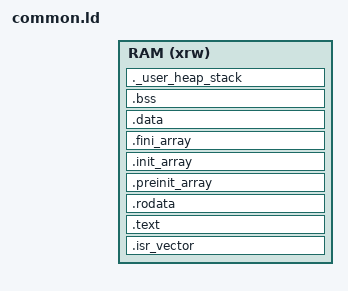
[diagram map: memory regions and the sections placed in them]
/* Common config for gcc's linker, as called from PlatformIO. Needs "ram.ld". */

/* Entry Point */
ENTRY(Reset_Handler)

_estack = ORIGIN(RAM) + LENGTH(RAM); /* end of "RAM" Ram type memory */

INCLUDE ram.ld
MEMORY
{
  RAM (xrw) : ORIGIN = RAM_BASE, LENGTH = RAM_SIZE
}

SECTIONS
{
  .isr_vector :
  {
    . = ALIGN(4);
    KEEP(*(.isr_vector))
    . = ALIGN(4);
  } >RAM

  .text :
  {
    . = ALIGN(4);
    *(.text)           /* .text sections (code) */
    *(.text*)          /* .text* sections (code) */
    *(.glue_7)         /* glue arm to thumb code */
    *(.glue_7t)        /* glue thumb to arm code */
    *(.eh_frame)

    KEEP (*(.init))
    KEEP (*(.fini))

    . = ALIGN(4);
    _etext = .;
  } >RAM

  .rodata :
  {
    . = ALIGN(4);
    *(.rodata)         /* .rodata sections (constants, strings, etc.) */
    *(.rodata*)        /* .rodata* sections (constants, strings, etc.) */
    . = ALIGN(4);
  } >RAM

  .preinit_array     :
  {
    . = ALIGN(4);
    PROVIDE_HIDDEN (__preinit_array_start = .);
    KEEP (*(.preinit_array*))
    PROVIDE_HIDDEN (__preinit_array_end = .);
    . = ALIGN(4);
  } >RAM

  .init_array :
  {
    . = ALIGN(4);
    PROVIDE_HIDDEN (__init_array_start = .);
    KEEP (*(SORT(.init_array.*)))
    KEEP (*(.init_array*))
    PROVIDE_HIDDEN (__init_array_end = .);
    . = ALIGN(4);
  } >RAM

  .fini_array :
  {
    . = ALIGN(4);
    PROVIDE_HIDDEN (__fini_array_start = .);
    KEEP (*(SORT(.fini_array.*)))
    KEEP (*(.fini_array*))
    PROVIDE_HIDDEN (__fini_array_end = .);
    . = ALIGN(4);
  } >RAM

  _sidata = LOADADDR(.data);

  .data :
  {
    . = ALIGN(4);
    _sdata = .;        /* create a global symbol at data start */
    *(.data)           /* .data sections */
    *(.data*)          /* .data* sections */
    *(.RamFunc)        /* .RamFunc sections */
    *(.RamFunc*)       /* .RamFunc* sections */

    . = ALIGN(4);
    _edata = .;

  } >RAM

  . = ALIGN(4);
  .bss :
  {
    _sbss = .;
    __bss_start__ = _sbss;
    *(.bss)
    *(.bss*)
    *(COMMON)

    . = ALIGN(4);
    _ebss = .;
    __bss_end__ = _ebss;
  } >RAM

  ._user_heap_stack :
  {
    . = ALIGN(8);
    PROVIDE ( end = . );
    PROVIDE ( _end = . );
    . = ALIGN(8);
  } >RAM

  /DISCARD/ :
  {
    libc.a ( * )
    libm.a ( * )
    libgcc.a ( * )
  }

  .ARM.attributes 0 : { *(.ARM.attributes) }
}
